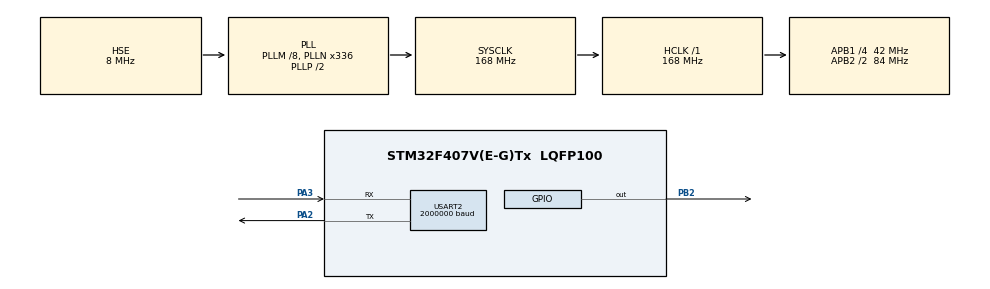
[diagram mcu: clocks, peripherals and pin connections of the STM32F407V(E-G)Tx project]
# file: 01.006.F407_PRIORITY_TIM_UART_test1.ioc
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Dma.Request0=USART2_TX
Dma.Request1=USART2_RX
Dma.USART2_RX.1.Direction=DMA_PERIPH_TO_MEMORY
Dma.USART2_RX.1.FIFOMode=DMA_FIFOMODE_DISABLE
Dma.USART2_RX.1.Instance=DMA1_Stream5
Dma.USART2_RX.1.MemDataAlignment=DMA_MDATAALIGN_BYTE
Dma.USART2_RX.1.MemInc=DMA_MINC_ENABLE
Dma.USART2_RX.1.Mode=DMA_CIRCULAR
Dma.USART2_RX.1.PeriphDataAlignment=DMA_PDATAALIGN_BYTE
Dma.USART2_RX.1.PeriphInc=DMA_PINC_DISABLE
Dma.USART2_RX.1.Priority=DMA_PRIORITY_LOW
Dma.USART2_TX.0.Direction=DMA_MEMORY_TO_PERIPH
Dma.USART2_TX.0.FIFOMode=DMA_FIFOMODE_DISABLE
Dma.USART2_TX.0.Instance=DMA1_Stream6
Dma.USART2_TX.0.MemDataAlignment=DMA_MDATAALIGN_BYTE
Dma.USART2_TX.0.MemInc=DMA_MINC_ENABLE
Dma.USART2_TX.0.Mode=DMA_NORMAL
Dma.USART2_TX.0.PeriphDataAlignment=DMA_PDATAALIGN_BYTE
Dma.USART2_TX.0.PeriphInc=DMA_PINC_DISABLE
Dma.USART2_TX.0.Priority=DMA_PRIORITY_LOW
Mcu.Family=STM32F4
Mcu.Name=STM32F407V(E-G)Tx
Mcu.Package=LQFP100
NVIC.DMA1_Stream5_IRQn=true\:0\:0\:false\:false\:true\:false\:true\:true
NVIC.DMA1_Stream6_IRQn=true\:0\:0\:false\:false\:true\:false\:true\:true
NVIC.PriorityGroup=NVIC_PRIORITYGROUP_0
NVIC.TIM2_IRQn=true\:0\:0\:true\:false\:true\:true\:true\:true
NVIC.USART2_IRQn=true\:0\:3\:false\:false\:true\:true\:true\:true
PA2.Mode=Asynchronous
PA2.Signal=USART2_TX
PA3.Mode=Asynchronous
PA3.Signal=USART2_RX
PB2.Signal=GPIO_Output
PH0-OSC_IN.Mode=HSE-External-Oscillator
PH0-OSC_IN.Signal=RCC_OSC_IN
PH1-OSC_OUT.Mode=HSE-External-Oscillator
PH1-OSC_OUT.Signal=RCC_OSC_OUT
ProjectManager.HeapSize=0x200
ProjectManager.StackSize=0x400
ProjectManager.TargetToolchain=STM32CubeIDE
RCC.48MHZClocksFreq_Value=48000000
RCC.AHBFreq_Value=168000000
RCC.APB1CLKDivider=RCC_HCLK_DIV4
RCC.APB1Freq_Value=42000000
RCC.APB1TimFreq_Value=84000000
RCC.APB2CLKDivider=RCC_HCLK_DIV2
RCC.APB2Freq_Value=84000000
RCC.APB2TimFreq_Value=168000000
RCC.CortexFreq_Value=168000000
RCC.HCLKFreq_Value=168000000
RCC.HSE_VALUE=8000000
RCC.HSI_VALUE=16000000
RCC.LSE_VALUE=32768
RCC.PLLM=8
RCC.PLLN=336
RCC.PLLQ=7
RCC.PLLSourceVirtual=RCC_PLLSOURCE_HSE
RCC.SYSCLKFreq_VALUE=168000000
RCC.SYSCLKSource=RCC_SYSCLKSOURCE_PLLCLK
RCC.VCOOutputFreq_Value=336000000
TIM2.Period=499
TIM2.Prescaler=8399
USART2.BaudRate=2000000
USART2.VirtualMode=VM_ASYNC
VP_TIM2_VS_ClockSourceINT.Mode=Internal
board=STM32F407G-DISC1

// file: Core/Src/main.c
/* USER CODE BEGIN Header */
/**
  ******************************************************************************
  * @file           : main.c
  * @brief          : Main program body
  ******************************************************************************
  * @attention
  *
  * Copyright (c) 2025 STMicroelectronics.
  * All rights reserved.
  *
  * This software is licensed under terms that can be found in the LICENSE file
  * in the root directory of this software component.
  * If no LICENSE file comes with this software, it is provided AS-IS.
  *
  ******************************************************************************
  */
/* USER CODE END Header */
#include "main.h"

/* USER CODE BEGIN Includes */

#include <stdio.h>
#include <string.h>
#include <stddef.h>
#include <stdarg.h>
#include <stdbool.h>
#include <stdlib.h>
/* USER CODE END Includes */

TIM_HandleTypeDef htim2;

UART_HandleTypeDef huart4;
DMA_HandleTypeDef hdma_usart2_tx;
DMA_HandleTypeDef hdma_usart2_rx;

/* USER CODE BEGIN PV */
uint8_t dma_rx_buffer[64];
uint16_t old_pos = 0;
/* USER CODE END PV */

void SystemClock_Config(void);
static void MX_GPIO_Init(void);
static void MX_DMA_Init(void);
static void MX_USART2_UART_Init(void);
static void MX_TIM2_Init(void);

/* USER CODE BEGIN 0 */
void DebugPrint(const char *format, ...)
{
    static char uartBuffer[250];  // <--- persists after function returns
    va_list args;
    va_start(args, format);
    vsnprintf(uartBuffer, sizeof(uartBuffer), format, args);
    va_end(args);

    HAL_UART_Transmit_DMA(&huart4, (uint8_t*)uartBuffer, strlen(uartBuffer));
}

void check_dma_data(void) {
    uint16_t pos = sizeof(dma_rx_buffer) - __HAL_DMA_GET_COUNTER(&hdma_usart2_rx);

    if (pos != old_pos) {
        if (pos > old_pos) {
            // Print new data
            for (uint16_t i = old_pos; i < pos; i++) {
                DebugPrint("\r\nGot: '%c' (0x%02X) at pos %d\r\n\r\n",
                       dma_rx_buffer[i], dma_rx_buffer[i], i);

            }
        }
        old_pos = pos;
    }
}

/* USER CODE END 0 */

int main(void)
{

  /* MCU Configuration--------------------------------------------------------*/

  /* Reset of all peripherals, Initializes the Flash interface and the Systick. */
  HAL_Init();

  /* Configure the system clock */
  SystemClock_Config();

  /* Initialize all configured peripherals */
  MX_GPIO_Init();
  MX_DMA_Init();
  MX_USART2_UART_Init();
  MX_TIM2_Init();
  /* USER CODE BEGIN 2 */
  HAL_TIM_Base_Start_IT(&htim2);

  HAL_UART_Receive_DMA(&huart4, dma_rx_buffer, sizeof(dma_rx_buffer));
  DebugPrint("DMA started! Type something...\r\n\r\n");
  /* USER CODE END 2 */

  /* Infinite loop */
  while (1)
  {

    /* USER CODE BEGIN 3 */
	  check_dma_data();
  }
  /* USER CODE END 3 */
}

void SystemClock_Config(void)
{
  RCC_OscInitTypeDef RCC_OscInitStruct = {0};
  RCC_ClkInitTypeDef RCC_ClkInitStruct = {0};

  /** Configure the main internal regulator output voltage
  */
  __HAL_RCC_PWR_CLK_ENABLE();
  __HAL_PWR_VOLTAGESCALING_CONFIG(PWR_REGULATOR_VOLTAGE_SCALE1);

  /** Initializes the RCC Oscillators according to the specified parameters
  * in the RCC_OscInitTypeDef structure.
  */
  RCC_OscInitStruct.OscillatorType = RCC_OSCILLATORTYPE_HSE;
  RCC_OscInitStruct.HSEState = RCC_HSE_ON;
  RCC_OscInitStruct.PLL.PLLState = RCC_PLL_ON;
  RCC_OscInitStruct.PLL.PLLSource = RCC_PLLSOURCE_HSE;
  RCC_OscInitStruct.PLL.PLLM = 8;
  RCC_OscInitStruct.PLL.PLLN = 336;
  RCC_OscInitStruct.PLL.PLLP = RCC_PLLP_DIV2;
  RCC_OscInitStruct.PLL.PLLQ = 7;
  if (HAL_RCC_OscConfig(&RCC_OscInitStruct) != HAL_OK)
  {
    Error_Handler();
  }

  /** Initializes the CPU, AHB and APB buses clocks
  */
  RCC_ClkInitStruct.ClockType = RCC_CLOCKTYPE_HCLK|RCC_CLOCKTYPE_SYSCLK
                              |RCC_CLOCKTYPE_PCLK1|RCC_CLOCKTYPE_PCLK2;
  RCC_ClkInitStruct.SYSCLKSource = RCC_SYSCLKSOURCE_PLLCLK;
  RCC_ClkInitStruct.AHBCLKDivider = RCC_SYSCLK_DIV1;
  RCC_ClkInitStruct.APB1CLKDivider = RCC_HCLK_DIV4;
  RCC_ClkInitStruct.APB2CLKDivider = RCC_HCLK_DIV2;

  if (HAL_RCC_ClockConfig(&RCC_ClkInitStruct, FLASH_LATENCY_5) != HAL_OK)
  {
    Error_Handler();
  }
}

static void MX_TIM2_Init(void)
{

  TIM_ClockConfigTypeDef sClockSourceConfig = {0};
  TIM_MasterConfigTypeDef sMasterConfig = {0};

  htim2.Instance = TIM2;
  htim2.Init.Prescaler = 8399;
  htim2.Init.CounterMode = TIM_COUNTERMODE_UP;
  htim2.Init.Period = 499;
  htim2.Init.ClockDivision = TIM_CLOCKDIVISION_DIV1;
  htim2.Init.AutoReloadPreload = TIM_AUTORELOAD_PRELOAD_DISABLE;
  if (HAL_TIM_Base_Init(&htim2) != HAL_OK)
  {
    Error_Handler();
  }
  sClockSourceConfig.ClockSource = TIM_CLOCKSOURCE_INTERNAL;
  if (HAL_TIM_ConfigClockSource(&htim2, &sClockSourceConfig) != HAL_OK)
  {
    Error_Handler();
  }
  sMasterConfig.MasterOutputTrigger = TIM_TRGO_RESET;
  sMasterConfig.MasterSlaveMode = TIM_MASTERSLAVEMODE_DISABLE;
  if (HAL_TIMEx_MasterConfigSynchronization(&htim2, &sMasterConfig) != HAL_OK)
  {
    Error_Handler();
  }

}

static void MX_USART2_UART_Init(void)
{

  huart4.Instance = USART2;
  huart4.Init.BaudRate = 2000000;
  huart4.Init.WordLength = UART_WORDLENGTH_8B;
  huart4.Init.StopBits = UART_STOPBITS_1;
  huart4.Init.Parity = UART_PARITY_NONE;
  huart4.Init.Mode = UART_MODE_TX_RX;
  huart4.Init.HwFlowCtl = UART_HWCONTROL_NONE;
  huart4.Init.OverSampling = UART_OVERSAMPLING_16;
  if (HAL_UART_Init(&huart4) != HAL_OK)
  {
    Error_Handler();
  }

}

static void MX_DMA_Init(void)
{

  /* DMA controller clock enable */
  __HAL_RCC_DMA1_CLK_ENABLE();

  /* DMA interrupt init */
  /* DMA1_Stream5_IRQn interrupt configuration */
  HAL_NVIC_SetPriority(DMA1_Stream5_IRQn, 0, 0);
  HAL_NVIC_EnableIRQ(DMA1_Stream5_IRQn);
  /* DMA1_Stream6_IRQn interrupt configuration */
  HAL_NVIC_SetPriority(DMA1_Stream6_IRQn, 0, 0);
  HAL_NVIC_EnableIRQ(DMA1_Stream6_IRQn);

}

static void MX_GPIO_Init(void)
{
  GPIO_InitTypeDef GPIO_InitStruct = {0};

  /* GPIO Ports Clock Enable */
  __HAL_RCC_GPIOH_CLK_ENABLE();
  __HAL_RCC_GPIOA_CLK_ENABLE();
  __HAL_RCC_GPIOB_CLK_ENABLE();

  /*Configure GPIO pin Output Level */
  HAL_GPIO_WritePin(GPIOB, GPIO_PIN_2, GPIO_PIN_RESET);

  /*Configure GPIO pin : PB2 */
  GPIO_InitStruct.Pin = GPIO_PIN_2;
  GPIO_InitStruct.Mode = GPIO_MODE_OUTPUT_PP;
  GPIO_InitStruct.Pull = GPIO_NOPULL;
  GPIO_InitStruct.Speed = GPIO_SPEED_FREQ_LOW;
  HAL_GPIO_Init(GPIOB, &GPIO_InitStruct);

}

/* USER CODE BEGIN 4 */
void HAL_TIM_PeriodElapsedCallback(TIM_HandleTypeDef *htim)
{
	if (htim->Instance == TIM2)
	{
		HAL_GPIO_TogglePin(GPIOB, GPIO_PIN_2);
	}

}
/* USER CODE END 4 */

void Error_Handler(void)
{
  __disable_irq();
  while (1)
  {
  }
}
